# STM32H7B0x register map
File version: 1.3
CPU: CM7 r0p1, little endian, MPU, FPU, 4 interrupt priority bits
Registers are 32-bit, read-write, reset 0x0 unless marked. A register's access mark holds for its fields unless they carry their own. Offsets are from the block's base; [hi:lo] are bit positions; {n}, {i} and the like mark numbered series; 'fields as' and 'values as' point back to an identical list.

## PF — Processor features
Base 0xE000ED78
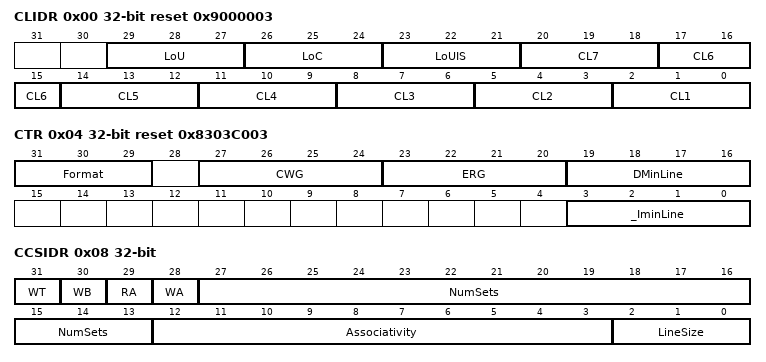
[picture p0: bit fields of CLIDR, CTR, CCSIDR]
0x00 CLIDR ro reset 0x9000003 — Cache Level ID register
  [29:27] LoU, [26:24] LoC, [23:21] LoUIS, [3n-1:3n-3] CL{n} (n=1..7)
0x04 CTR ro reset 0x8303C003 — Cache Type register
  [31:29] Format, [27:24] CWG, [23:20] ERG, [19:16] DMinLine, [3:0] _IminLine
0x08 CCSIDR ro — Cache Size ID register
  [31] WT, [30] WB, [29] RA, [28] WA, [27:13] NumSets, [12:3] Associativity, [2:0] LineSize

## AC — Access control
Base 0xE000EF90
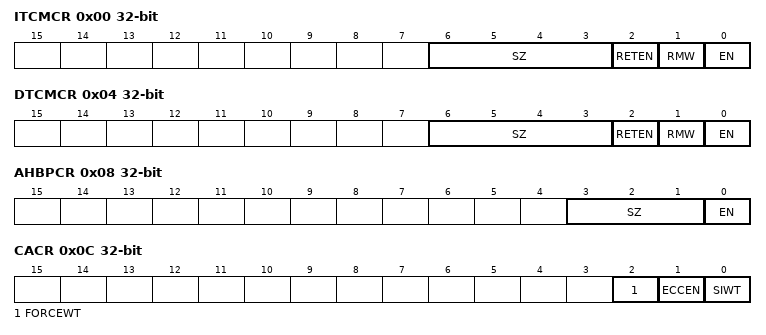
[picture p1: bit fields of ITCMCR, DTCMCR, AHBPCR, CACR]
0x00 ITCMCR — Instruction and Data Tightly-Coupled Memory Control Registers
  [6:3] SZ, [2] RETEN, [1] RMW, [0] EN
0x04 DTCMCR — Instruction and Data Tightly-Coupled Memory Control Registers
  [6:3] SZ, [2] RETEN, [1] RMW, [0] EN
0x08 AHBPCR — AHBP Control register
  [3:1] SZ, [0] EN
0x0C CACR — Auxiliary Cache Control register
  [2] FORCEWT, [1] ECCEN, [0] SIWT
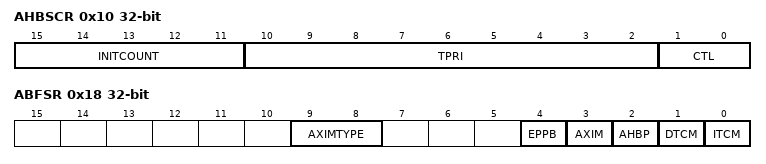
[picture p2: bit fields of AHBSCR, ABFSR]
0x10 AHBSCR — AHB Slave Control register
  [15:11] INITCOUNT, [10:2] TPRI, [1:0] CTL
0x18 ABFSR — Auxiliary Bus Fault Status register
  [9:8] AXIMTYPE, [4] EPPB, [3] AXIM, [2] AHBP, [1] DTCM, [0] ITCM

## OctoSPII_O_Manager
Base 0x5200B400
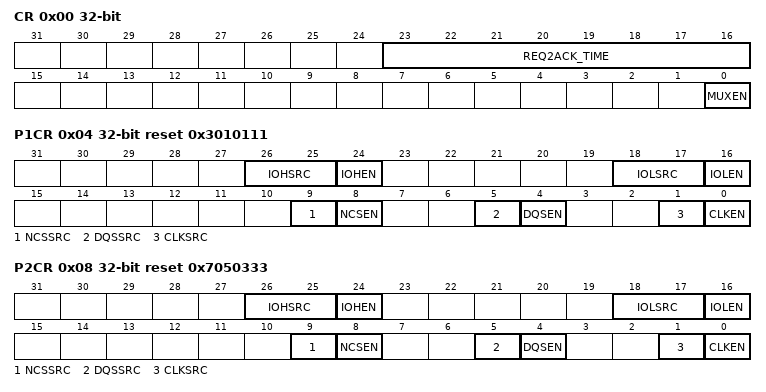
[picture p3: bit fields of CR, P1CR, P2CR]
0x00 CR — OctoSPI IO Manager Control Register
  [23:16] REQ2ACK_TIME — REQ to ACK Time
  [0] MUXEN — Multiplexed mode Enable
0x04 P1CR reset 0x3010111 — OctoSPI IO Manager Port 1 configuration register
  [26:25] IOHSRC
  [24] IOHEN
  [18:17] IOLSRC
  [16] IOLEN
  [9] NCSSRC
  [8] NCSEN
  [5] DQSSRC
  [4] DQSEN
  [1] CLKSRC — CLK/CLKn Source for Port n
  [0] CLKEN — CLK/CLKn Enable for Port n
0x08 P2CR reset 0x7050333 — OctoSPI IO Manager Port 2 configuration register
  [26:25] IOHSRC, [24] IOHEN, [18:17] IOLSRC, [16] IOLEN, [9] NCSSRC, [8] NCSEN, [5] DQSSRC, [4] DQSEN, [1] CLKSRC, [0] CLKEN

## OTFDEC1 — On-The-Fly Decryption engine
Base 0x5200B800
Same registers: OTFDEC2 0x5200BC00
0x00 CR — OTFDEC control register
  [0] ENC — Encryption mode bit
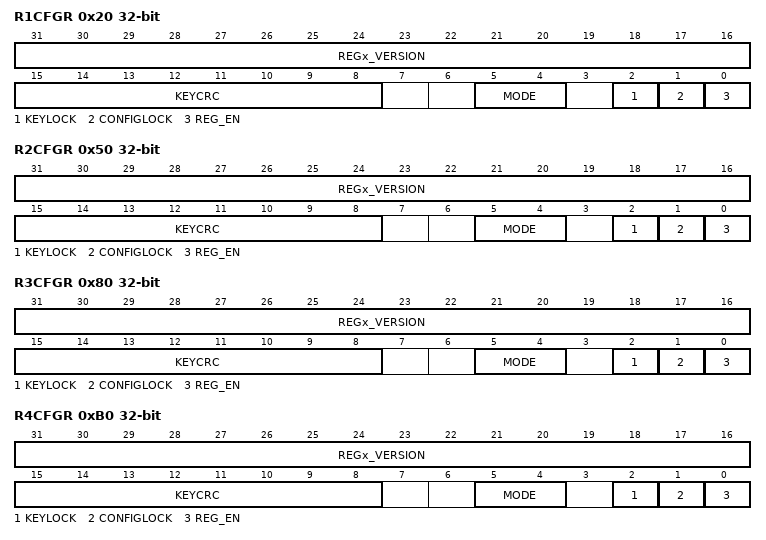
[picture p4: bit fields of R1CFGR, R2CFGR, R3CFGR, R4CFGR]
0x20 R1CFGR access per field — OTFDEC region x configuration register
  [31:16] REGx_VERSION rw — region firmware version
  [15:8] KEYCRC ro — region key 8-bit CRC
  [5:4] MODE rw — operating mode
  [2] KEYLOCK rw — region key lock
  [1] CONFIGLOCK rw — region config lock
  [0] REG_EN rw — region on-the-fly decryption enable
0x24 R1STARTADDR — OTFDEC region x start address register
  [31:0] REGx_START_ADDR — Region AXI start address
0x28 R1ENDADDR reset 0xFFF — OTFDEC region x end address register
  [31:0] REGx_END_ADDR — Region AXI end address
0x2C R1NONCER0 — OTFDEC region x nonce register 0
  [31:0] REGx_NONCE
0x30 R1NONCER1 — OTFDEC region x nonce register 1
  [31:0] REGx_NONCE — Region nonce
{0x4+0x30*i} R{i}KEYR0 wo (i=1..4) — OTFDEC region x key register 0
  [31:0] REGx_KEY
{0x8+0x30*i} R{i}KEYR1 wo (i=1..4) — OTFDEC region x key register 1
  [31:0] REGx_KEY
0x3C R1KEYR2 wo — OTFDEC region x key register 2
  [31:0] REGx_KEY
{0x10+0x30*i} R{i}KEYR3 wo (i=1..4) — OTFDEC region x key register 3
  [31:0] REGx_KEY
0x50 R2CFGR access per field — OTFDEC region x configuration register
  fields as R1CFGR
0x54 R2STARTADDR — OTFDEC region x start address register
  [31:0] REGx_START_ADDR — Region AXI start address
0x58 R2ENDADDR reset 0xFFF — OTFDEC region x end address register
  [31:0] REGx_END_ADDR — Region AXI end address
0x5C R2NONCER0 — OTFDEC region x nonce register 0
  [31:0] REGx_NONCE
0x60 R2NONCER1 — OTFDEC region x nonce register 1
  [31:0] REGx_NONCE — Region nonce, bits [63:32]REGx_NONCE[63:32]
0x6C R2KEYR2 wo — OTFDEC region x key register 2
  [31:0] REGx_KEY_
0x80 R3CFGR access per field — OTFDEC region x configuration register
  fields as R1CFGR
0x84 R3STARTADDR — OTFDEC region x start address register
  [31:0] REGx_START_ADDR — Region AXI start address
0x88 R3ENDADDR reset 0xFFF — OTFDEC region x end address register
  [31:0] REGx_END_ADDR — Region AXI end address
0x8C R4ENDADDR reset 0xFFF — OTFDEC region x end address register
  [31:0] REGx_END_ADDR — Region AXI end address
0x8C R3NONCER0 (alternate view of R4ENDADDR) — OTFDEC region x nonce register 0
  [31:0] REGx_NONCE
0x90 R3NONCER1 — OTFDEC region x nonce register 1
  [31:0] REGx_NONCE
0x9C R3KEYR2 wo — OTFDEC region x key register 2
  [31:0] REGx_KEY
0xB0 R4CFGR access per field — OTFDEC region x configuration register
  fields as R1CFGR
0xB4 R4STARTADDR — OTFDEC region x start address register
  [31:0] REGx_START_ADDR — Region AXI start address
0xBC R4NONCER0 — OTFDEC region x nonce register 0
  [31:0] REGx_NONCE
0xC0 R4NONCER1 — OTFDEC region x nonce register 1
  [31:0] REGx_NONCE
0xCC R4KEYR2 wo — OTFDEC region x key register 2
  [31:0] REGx_KEY
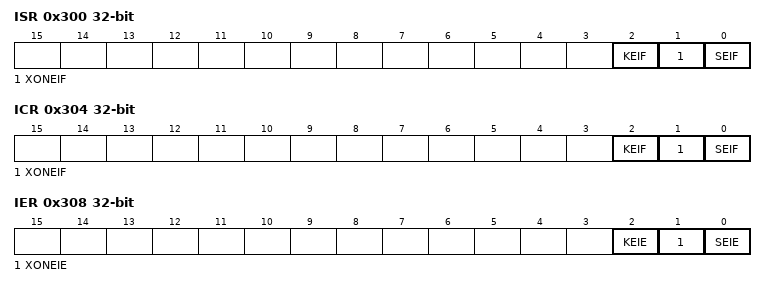
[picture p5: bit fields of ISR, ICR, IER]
0x300 ISR ro — OTFDEC interrupt status register
  [2] KEIF — Key Error Interrupt Flag status
  [1] XONEIF — Execute-only execute-Never Error Interrupt Flag status
  [0] SEIF — Security Error Interrupt Flag status
0x304 ICR ro — OTFDEC interrupt clear register
  [2] KEIF
  [1] XONEIF — Execute-only execute-Never Error Interrupt Flag clear
  [0] SEIF
0x308 IER — OTFDEC interrupt enable register
  [2] KEIE
  [1] XONEIE
  [0] SEIE — Security Error Interrupt Enable
